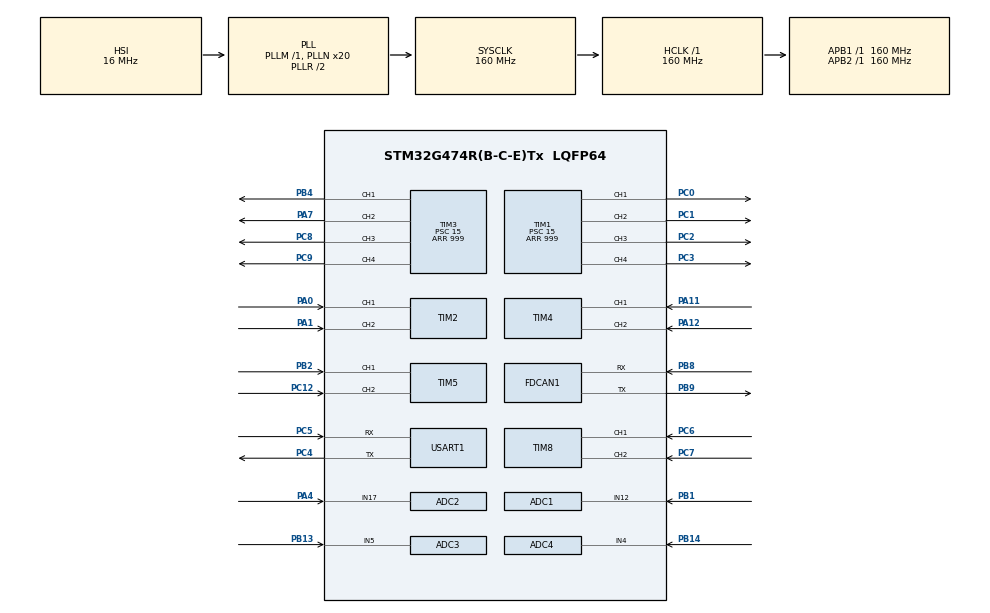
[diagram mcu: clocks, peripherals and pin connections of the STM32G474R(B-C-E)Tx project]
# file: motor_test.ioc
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ADC1.Channel-1\#ChannelRegularConversion=ADC_CHANNEL_12
ADC1.NbrOfConversionFlag=1
ADC1.OffsetNumber-1\#ChannelRegularConversion=ADC_OFFSET_NONE
ADC1.Rank-1\#ChannelRegularConversion=1
ADC1.SamplingTime-1\#ChannelRegularConversion=ADC_SAMPLETIME_2CYCLES_5
ADC1.master=1
ADC2.Channel-0\#ChannelRegularConversion=ADC_CHANNEL_17
ADC2.NbrOfConversionFlag=1
ADC2.OffsetNumber-0\#ChannelRegularConversion=ADC_OFFSET_NONE
ADC2.Rank-0\#ChannelRegularConversion=1
ADC2.SamplingTime-0\#ChannelRegularConversion=ADC_SAMPLETIME_2CYCLES_5
ADC3.Channel-0\#ChannelRegularConversion=ADC_CHANNEL_5
ADC3.DataAlign=ADC_DATAALIGN_LEFT
ADC3.NbrOfConversionFlag=1
ADC3.OffsetNumber-0\#ChannelRegularConversion=ADC_OFFSET_NONE
ADC3.Rank-0\#ChannelRegularConversion=1
ADC3.SamplingTime-0\#ChannelRegularConversion=ADC_SAMPLETIME_2CYCLES_5
ADC3.master=1
ADC4.Channel-0\#ChannelRegularConversion=ADC_CHANNEL_4
ADC4.NbrOfConversionFlag=1
ADC4.OffsetNumber-0\#ChannelRegularConversion=ADC_OFFSET_NONE
ADC4.Rank-0\#ChannelRegularConversion=1
ADC4.SamplingTime-0\#ChannelRegularConversion=ADC_SAMPLETIME_2CYCLES_5
FDCAN1.AutoRetransmission=DISABLE
FDCAN1.CalculateBaudRateNominal=500000
FDCAN1.CalculateTimeBitNominal=2000
FDCAN1.CalculateTimeQuantumNominal=25.0
FDCAN1.DataPrescaler=4
FDCAN1.DataSyncJumpWidth=10
FDCAN1.DataTimeSeg1=9
FDCAN1.DataTimeSeg2=10
FDCAN1.FrameFormat=FDCAN_FRAME_FD_BRS
FDCAN1.NominalPrescaler=4
FDCAN1.NominalSyncJumpWidth=20
FDCAN1.NominalTimeSeg1=59
FDCAN1.NominalTimeSeg2=20
Mcu.Family=STM32G4
Mcu.Name=STM32G474R(B-C-E)Tx
Mcu.Package=LQFP64
NVIC.FDCAN1_IT0_IRQn=true\:0\:0\:false\:false\:true\:true\:true\:true
NVIC.PriorityGroup=NVIC_PRIORITYGROUP_4
PA0.Signal=S_TIM2_CH1
PA1.Signal=S_TIM2_CH2
PA11.Signal=S_TIM4_CH1
PA12.Signal=S_TIM4_CH2
PA13.Mode=Trace_Asynchronous_SW
PA13.Signal=SYS_JTMS-SWDIO
PA14.Mode=Trace_Asynchronous_SW
PA14.Signal=SYS_JTCK-SWCLK
PA4.Mode=IN17-Single-Ended
PA4.Signal=ADC2_IN17
PA7.Signal=S_TIM3_CH2
PB1.Mode=IN12-Single-Ended
PB1.Signal=ADC1_IN12
PB13.Mode=IN5-Single-Ended
PB13.Signal=ADC3_IN5
PB14.Mode=IN4-Single-Ended
PB14.Signal=ADC4_IN4
PB2.Signal=S_TIM5_CH1
PB3.Mode=Trace_Asynchronous_SW
PB3.Signal=SYS_JTDO-SWO
PB4.Signal=S_TIM3_CH1
PB8-BOOT0.Mode=FDCAN_Activate
PB8-BOOT0.Signal=FDCAN1_RX
PB9.Mode=FDCAN_Activate
PB9.Signal=FDCAN1_TX
PC0.Signal=S_TIM1_CH1
PC1.Signal=S_TIM1_CH2
PC12.Signal=S_TIM5_CH2
PC2.Signal=S_TIM1_CH3
PC3.Signal=S_TIM1_CH4
PC4.Mode=Asynchronous
PC4.Signal=USART1_TX
PC5.Mode=Asynchronous
PC5.Signal=USART1_RX
PC6.Signal=S_TIM8_CH1
PC7.Signal=S_TIM8_CH2
PC8.Signal=S_TIM3_CH3
PC9.Signal=S_TIM3_CH4
PF0-OSC_IN.Mode=HSE-External-Oscillator
PF0-OSC_IN.Signal=RCC_OSC_IN
PF1-OSC_OUT.Mode=HSE-External-Oscillator
PF1-OSC_OUT.Signal=RCC_OSC_OUT
ProjectManager.HeapSize=0x200
ProjectManager.StackSize=0x400
ProjectManager.TargetToolchain=STM32CubeIDE
RCC.ADC12Freq_Value=160000000
RCC.ADC345Freq_Value=160000000
RCC.AHBFreq_Value=160000000
RCC.APB1Freq_Value=160000000
RCC.APB1TimFreq_Value=160000000
RCC.APB2Freq_Value=160000000
RCC.APB2TimFreq_Value=160000000
RCC.CortexFreq_Value=160000000
RCC.EXTERNAL_CLOCK_VALUE=12288000
RCC.HCLKFreq_Value=160000000
RCC.HSE_VALUE=16000000
RCC.HSI48_VALUE=48000000
RCC.HSI_VALUE=16000000
RCC.LSE_VALUE=32768
RCC.PLLN=20
RCC.SYSCLKFreq_VALUE=160000000
RCC.SYSCLKSource=RCC_SYSCLKSOURCE_PLLCLK
RCC.USBFreq_Value=160000000
RCC.VCOOutputFreq_Value=320000000
SH.S_TIM1_CH1.0=TIM1_CH1,PWM Generation1 CH1
SH.S_TIM1_CH2.0=TIM1_CH2,PWM Generation2 CH2
SH.S_TIM1_CH3.0=TIM1_CH3,PWM Generation3 CH3
SH.S_TIM1_CH4.0=TIM1_CH4,PWM Generation4 CH4
SH.S_TIM2_CH1.0=TIM2_CH1,Encoder_Interface
SH.S_TIM2_CH2.0=TIM2_CH2,Encoder_Interface
SH.S_TIM3_CH1.0=TIM3_CH1,PWM Generation1 CH1
SH.S_TIM3_CH2.0=TIM3_CH2,PWM Generation2 CH2
SH.S_TIM3_CH3.0=TIM3_CH3,PWM Generation3 CH3
SH.S_TIM3_CH4.0=TIM3_CH4,PWM Generation4 CH4
SH.S_TIM4_CH1.0=TIM4_CH1,Encoder_Interface
SH.S_TIM4_CH2.0=TIM4_CH2,Encoder_Interface
SH.S_TIM5_CH1.0=TIM5_CH1,Encoder_Interface
SH.S_TIM5_CH2.0=TIM5_CH2,Encoder_Interface
SH.S_TIM8_CH1.0=TIM8_CH1,Encoder_Interface
SH.S_TIM8_CH2.0=TIM8_CH2,Encoder_Interface
TIM1.Channel-PWM\ Generation1\ CH1=TIM_CHANNEL_1
TIM1.Channel-PWM\ Generation2\ CH2=TIM_CHANNEL_2
TIM1.Channel-PWM\ Generation3\ CH3=TIM_CHANNEL_3
TIM1.Channel-PWM\ Generation4\ CH4=TIM_CHANNEL_4
TIM1.PeriodNoDither=999
TIM1.Prescaler=15
TIM3.Channel-PWM\ Generation1\ CH1=TIM_CHANNEL_1
TIM3.Channel-PWM\ Generation2\ CH2=TIM_CHANNEL_2
TIM3.Channel-PWM\ Generation3\ CH3=TIM_CHANNEL_3
TIM3.Channel-PWM\ Generation4\ CH4=TIM_CHANNEL_4
TIM3.PeriodNoDither=999
TIM3.Prescaler=15
USART1.VirtualMode-Asynchronous=VM_ASYNC
VP_SYS_VS_DBSignals.Mode=DisableDeadBatterySignals
board=custom

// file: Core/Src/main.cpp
/* USER CODE BEGIN Header */
/**
  ******************************************************************************
  * @file           : main.c
  * @brief          : Main program body
  ******************************************************************************
  * @attention
  *
  * Copyright (c) 2024 STMicroelectronics.
  * All rights reserved.
  *
  * This software is licensed under terms that can be found in the LICENSE file
  * in the root directory of this software component.
  * If no LICENSE file comes with this software, it is provided AS-IS.
  *
  ******************************************************************************
  */
/* USER CODE END Header */
#include "main.h"
#include "adc.h"
#include "fdcan.h"
#include "tim.h"
#include "usart.h"
#include "gpio.h"
/* USER CODE BEGIN Includes */
#include "../driver/app.hpp"
/* USER CODE END Includes */

void SystemClock_Config(void);

int main(void)
{

  /* MCU Configuration--------------------------------------------------------*/

  /* Reset of all peripherals, Initializes the Flash interface and the Systick. */
  HAL_Init();

  /* Configure the system clock */
  SystemClock_Config();

  /* Initialize all configured peripherals */
  MX_GPIO_Init();
  MX_TIM3_Init();
  MX_TIM5_Init();
  MX_USART1_UART_Init();
  MX_ADC1_Init();
  MX_TIM4_Init();
  MX_TIM1_Init();
  MX_FDCAN1_Init();
  MX_TIM8_Init();
  MX_ADC3_Init();
  MX_ADC2_Init();
  MX_ADC4_Init();
  MX_TIM2_Init();
  /* USER CODE BEGIN 2 */
  if (!app.Initilized()) Error_Handler();
  app.loop();
  /* USER CODE END 2 */
}

void HAL_FDCAN_RxFifo0Callback(FDCAN_HandleTypeDef *hfdcan, uint32_t RxFifo0ITs) {
  if((RxFifo0ITs & FDCAN_IT_RX_FIFO0_NEW_MESSAGE) != RESET) {
	  canfd->rx_interrupt_task();
  }
}
void SystemClock_Config(void)
{
  RCC_OscInitTypeDef RCC_OscInitStruct = {0};
  RCC_ClkInitTypeDef RCC_ClkInitStruct = {0};

  /** Configure the main internal regulator output voltage
  */
  HAL_PWREx_ControlVoltageScaling(PWR_REGULATOR_VOLTAGE_SCALE1_BOOST);

  /** Initializes the RCC Oscillators according to the specified parameters
  * in the RCC_OscInitTypeDef structure.
  */
  RCC_OscInitStruct.OscillatorType = RCC_OSCILLATORTYPE_HSI;
  RCC_OscInitStruct.HSIState = RCC_HSI_ON;
  RCC_OscInitStruct.HSICalibrationValue = RCC_HSICALIBRATION_DEFAULT;
  RCC_OscInitStruct.PLL.PLLState = RCC_PLL_ON;
  RCC_OscInitStruct.PLL.PLLSource = RCC_PLLSOURCE_HSI;
  RCC_OscInitStruct.PLL.PLLM = RCC_PLLM_DIV1;
  RCC_OscInitStruct.PLL.PLLN = 20;
  RCC_OscInitStruct.PLL.PLLP = RCC_PLLP_DIV2;
  RCC_OscInitStruct.PLL.PLLQ = RCC_PLLQ_DIV2;
  RCC_OscInitStruct.PLL.PLLR = RCC_PLLR_DIV2;
  if (HAL_RCC_OscConfig(&RCC_OscInitStruct) != HAL_OK)
  {
    Error_Handler();
  }

  /** Initializes the CPU, AHB and APB buses clocks
  */
  RCC_ClkInitStruct.ClockType = RCC_CLOCKTYPE_HCLK|RCC_CLOCKTYPE_SYSCLK
                              |RCC_CLOCKTYPE_PCLK1|RCC_CLOCKTYPE_PCLK2;
  RCC_ClkInitStruct.SYSCLKSource = RCC_SYSCLKSOURCE_PLLCLK;
  RCC_ClkInitStruct.AHBCLKDivider = RCC_SYSCLK_DIV1;
  RCC_ClkInitStruct.APB1CLKDivider = RCC_HCLK_DIV1;
  RCC_ClkInitStruct.APB2CLKDivider = RCC_HCLK_DIV1;

  if (HAL_RCC_ClockConfig(&RCC_ClkInitStruct, FLASH_LATENCY_4) != HAL_OK)
  {
    Error_Handler();
  }
}

void Error_Handler(void)
{
  __disable_irq();
  while (1)
  {
  }
}
